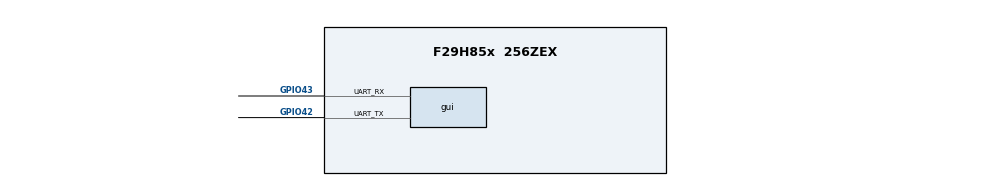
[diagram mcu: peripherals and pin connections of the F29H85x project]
/**
 * @cliArgs --device "F29H85x" --package "256ZEX" --part "F29H85x_256ZEX" --context "CPU1" --product "MCU_SDK_F29H85x@1.00.00.00"
 * @versions {"tool":"1.22.0+3877"}
 */

const divider15       = system.clockTree["PLL_REFDIV"];
divider15.divideValue = 1;

const multiplier1         = system.clockTree["PLL_IMULT"];
multiplier1.multiplyValue = 40;

const mux7       = system.clockTree["OSCCLKSRCSEL"];
mux7.inputSelect = "INTOSC2";
/**
 * Import the modules used in this configuration.
 */
const sysctl         = scripting.addModule("/driverlib/sysctl.js");
const gui            = scripting.addModule("/transfer/gui.js");

gui.customlogger                                        = true;
gui.guiProjectName                                      = "transfer_customlog_export_uart";
gui.exporter.$name                                      = "myEXPORT0";
gui.exporter.exportCustomLogTimestamp                   = true;
gui.exporter.comsLinkModule.uart.$assign                = "UARTA";
gui.exporter.comsLinkModule.uart.uart_txPin.$assign     = "GPIO42";
gui.exporter.comsLinkModule.uart.uart_rxPin.$assign     = "GPIO43";
gui.exporter.comsLinkModule.txQual.$name                = "myGPIOQUAL0";
gui.exporter.comsLinkModule.rxQual.$name                = "myGPIOQUAL1";
gui.exporter.comsLinkModule.periphClock.$name           = "driverlib_perClock0";
gui.exporter.comsLinkModule.periphConfig.$name          = "driverlib_perConfig0";
gui.exporter.exportLogTimestampModule.periphClock.$name = "driverlib_perClock1";
